# liliumFP1_secure register map
Vendor: Nordic Semiconductor; Series: liliumFP1; File version: 1
CPU: CM33 r0p4, little endian, MPU, FPU, 3 interrupt priority bits, 480 interrupts
Registers are 32-bit, read-write, reset 0x0 unless marked. A register's access mark holds for its fields unless they carry their own. Offsets are from the block's base; [hi:lo] are bit positions; lines under a group give offsets from that group; {n}, {i} and the like mark numbered series; 'fields as' and 'values as' point back to an identical list.

## CPUCONF_NS — CPU Configuration 0
Base 0x41011000
Same registers: CPUCONF_S 0x51011000
0x00 TASKS_ERASECACHE wo — Erase the caches used by the CPU.
  [0] TASKS_ERASECACHE
    1=Trigger task
0x500 INITSVTOR reset 0x1000000 — Initial value of the secure VTOR (Vector Table Offset Register) after CPU reset.
  [31:0] INITSVTOR — Initial value of the VTOR.
0x504 INITNSVTOR reset 0x1000000 — Initial value of the non-secure VTOR (Vector Table Offset Register).
  [31:0] INITNSVTOR — Initial value of the VTOR.
0x508 CPUSTART reset 0x1 — Enable for starting the CPU
  [0] EN — Enable to start the CPU.
    0=Stopped (CPU stopped.); 1=Started (CPU started.)
0x50C CPUWAIT — Enable for the CPU wait.
  [0] EN — Enable to the CPU wait.
    0=Disabled (CPU is not waiting.); 1=Enabled (CPU is waiting.)

## MEMCONF_NS — Memory configuration 0
Base 0x41012000
Same registers: MEMCONF_S 0x51012000, MEMCONF200_S 0xBF014000
{0x500+0x10*i} POWER[{i}] (i=0..3) group — Unspecified
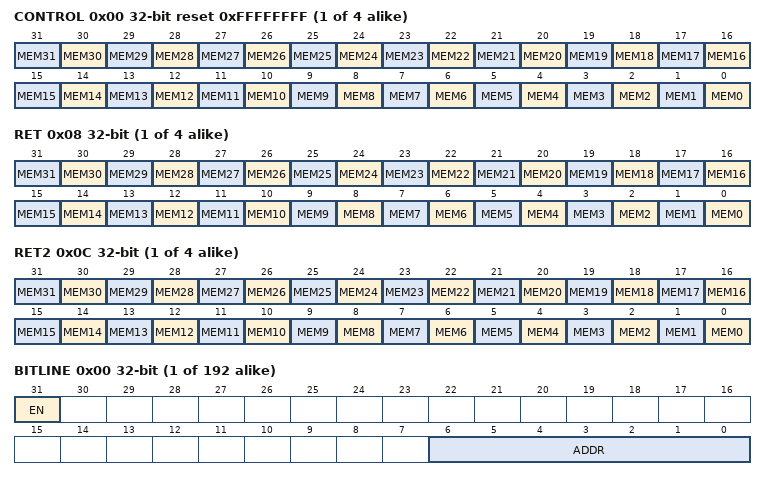
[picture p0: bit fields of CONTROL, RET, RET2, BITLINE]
  0x00 CONTROL reset 0xFFFFFFFF — Description cluster: RAM/ROM[n] power control register.
    [all] fields
      0=Off (Power down); 1=On (Power up)
    [n] MEM{n} (n=0..31) — Keep the RAM/ROM block MEM[{n}] on or off when in System ON mode.
  0x08 RET — Description cluster: RAM retention for RAM [n].
    [all] fields
      0=Off (Retention off); 1=On (Retention on)
    [n] MEM{n} (n=0..31) — Keep the RAM block MEM[{n}] retained when in System OFF mode.
  0x0C RET2 — Description cluster: RAM retention for the second bank in the RAM block
    [all] fields
      0=Off (Retention off); 1=On (Retention on)
    [n] MEM{n} (n=0..31) — Keep the second bank in RAM block MEM[{n}] retained when in System OFF mode.
{0x600+4i} REPAIR[{i}] (i=0..191) group — Unspecified
  0x00 BITLINE — Description cluster: Repair configuration for RAM blocks.
    [31] EN — Enable bitline repair
      0=Disabled (Repair disabled.); 1=Enabled (Repair enabled.)
    [6:0] ADDR — Repair address of the bitline
{0x900+4i} BLOCKTYPE[{i}] (i=0..63) group — Unspecified
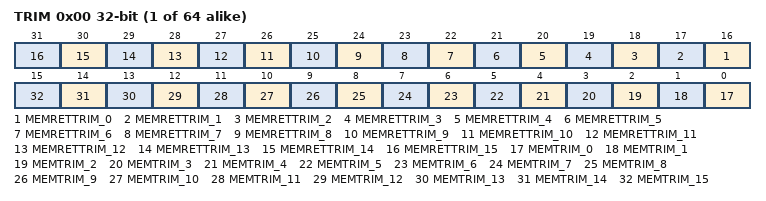
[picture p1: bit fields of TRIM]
  0x00 TRIM — Description cluster: Trim configuration for the RAM/ROM block types.
    [n+16] MEMRETTRIM_{n} (n=0..15) — Trimming for retention mode for decreased leakage. Must be kept active in RAM retention mode.
    [n] MEMTRIM_{n} (n=0..15) — Read/write margin trim.

## MUTEX_NS — MUTEX 0
Base 0x41017000
Same registers: MUTEX_S 0x51017000
{0x400+4i} MUTEX[{i}] (i=0..7) — Description collection: Mutex register
  [0] MUTEX — Mutex register n
    0=Unlocked (Mutex n is in unlocked state); 1=Locked (Mutex n is in locked state)

## BILS_S — The Built-in Leakage Sensor (BILS) module.
Base 0x51019000
0x400 CONFIG group — Unspecified
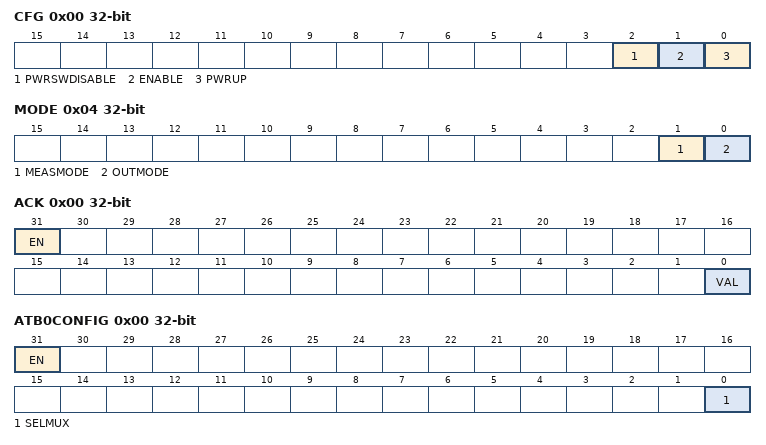
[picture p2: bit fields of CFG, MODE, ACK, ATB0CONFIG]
  0x00 CFG — BILS configuration
    [2] PWRSWDISABLE — Disable power switch.
      0=PwrSwNormalMode (Normal control of the power switch.); 1=PwrSwDisabledMode (Power switch is turned off.)
    [1] ENABLE — BILS enable
      0=BilsDisable (Disable BILS, REQ_SWOFF_AO_0V8 = 0); 1=BilsEnable (Enable BILS, REQ_SWOFF_AO_0V8 is controlled by BILS)
    [0] PWRUP — Power up BILS
      0=PwrOff (BILS is powered down and REQ_SWOFF_AO_0V8=0); 1=PwrOn (BILS is powered up)
  0x04 MODE — Mode selection
    [1] MEASMODE — Measurement mode selection
      0=MeasDisMode (Measure discharge rate); 1=MeasPwMode (Measure power switch chain propagation delay)
    [0] OUTMODE — Output mode selection
      0=Duty50Mode (50:50 duty cycle output selected to FOUT_AO_0V8 pin); 1=CompMode (Comparator output selected to FOUT_AO_0V8 pin)
0x500 OVERRIDE group — Unspecified
  0x00 ACK — Override the ACL_SWOFF_0V8 signal
    [31] EN — Override enable
      0=Disabled (Override disabled); 1=Enabled (Override is enabled)
    [0] VAL — Override value
0x600 DFT group — Unspecified
  0x00 ATB0CONFIG — Analog Test Bus 0 (ATB0) configuration
    [31] EN — Enable the analog test bus
      0=Disabled (Analog test bus is disabled); 1=Enabled (Analog test bus is enabled)
    [0] SELMUX — Select multiplexer for ATB0
      0=None selected; 1=Connect (Voltage on ATB0 used as threshold voltage)
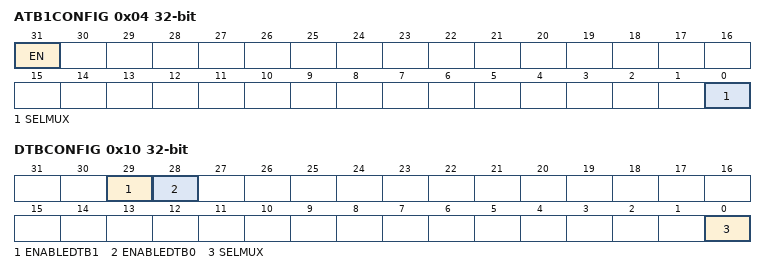
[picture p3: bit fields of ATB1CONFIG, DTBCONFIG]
  0x04 ATB1CONFIG — Analog Test Bus 1 (ATB1) configuration
    [31] EN — Enable the analog test bus
      values as DFT.ATB0CONFIG.EN
    [0] SELMUX — Select multiplexer for ATB1
      0=None selected; 1=ConnectDVDD (ATB1 connected to DVDD_0V8_SW)
  0x10 DTBCONFIG — Digital Test Bus configuration
    [29] ENABLEDTB1 — Enable the digital test bus
      0=Disabled (Digital test bus is disabled); 1=Enabled (Digital test bus is enabled)
    [28] ENABLEDTB0 — Enable the digital test bus
      values as ENABLEDTB1
    [0] SELMUX — Select multiplexer for DTB0
      0=None selected; 1=Connect (FOUT_AO_0V8 is connected to DTB0, REQ_SWOFF_AO_0V8 is connected to DTB1)

## Notices in the file
Copyright (c) 2010 - 2022, Nordic Semiconductor ASA
All rights reserved.
Redistribution and use in source and binary forms, with or without modification,
are permitted provided that the following conditions are met:
1. Redistributions of source code must retain the above copyright notice, this
list of conditions and the following disclaimer.
2. Redistributions in binary form, except as embedded into a Nordic
Semiconductor ASA integrated circuit in a product or a software update for
such product, must reproduce the above copyright notice, this list of
conditions and the following disclaimer in the documentation and/or other
materials provided with the distribution.
3. Neither the name of Nordic Semiconductor ASA nor the names of its
contributors may be used to endorse or promote products derived from this
software without specific prior written permission.
4. This software, with or without modification, must only be used with a
Nordic Semiconductor ASA integrated circuit.
5. Any software provided in binary form under this license must not be reverse
engineered, decompiled, modified and/or disassembled.
THIS SOFTWARE IS PROVIDED BY NORDIC SEMICONDUCTOR ASA "AS IS" AND ANY EXPRESS
OR IMPLIED WARRANTIES, INCLUDING, BUT NOT LIMITED TO, THE IMPLIED WARRANTIES
OF MERCHANTABILITY, NONINFRINGEMENT, AND FITNESS FOR A PARTICULAR PURPOSE ARE
DISCLAIMED. IN NO EVENT SHALL NORDIC SEMICONDUCTOR ASA OR CONTRIBUTORS BE
LIABLE FOR ANY DIRECT, INDIRECT, INCIDENTAL, SPECIAL, EXEMPLARY, OR
CONSEQUENTIAL DAMAGES (INCLUDING, BUT NOT LIMITED TO, PROCUREMENT OF SUBSTITUTE
GOODS OR SERVICES; LOSS OF USE, DATA, OR PROFITS; OR BUSINESS INTERRUPTION)
HOWEVER CAUSED AND ON ANY THEORY OF LIABILITY, WHETHER IN CONTRACT, STRICT
LIABILITY, OR TORT (INCLUDING NEGLIGENCE OR OTHERWISE) ARISING IN ANY WAY OUT
OF THE USE OF THIS SOFTWARE, EVEN IF ADVISED OF THE POSSIBILITY OF SUCH DAMAGE.
